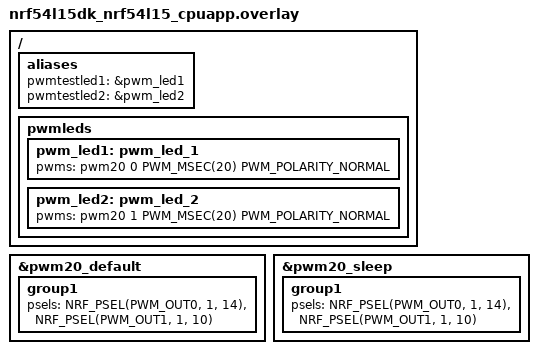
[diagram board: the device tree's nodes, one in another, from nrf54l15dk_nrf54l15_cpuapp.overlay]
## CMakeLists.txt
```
cmake_minimum_required(VERSION 3.20.0)
find_package(Zephyr REQUIRED HINTS $ENV{ZEPHYR_BASE})

project(pwm_test)

target_sources(app PRIVATE src/main.c)
```

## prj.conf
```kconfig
# Logging
CONFIG_LOG=y

# STEP 1.1 - Enable PWM
CONFIG_PWM=y
CONFIG_PWM_LOG_LEVEL_DBG=y

# STEP 1.2 - Enable LED and LED PWM
CONFIG_LED=y
CONFIG_LED_PWM=y
```

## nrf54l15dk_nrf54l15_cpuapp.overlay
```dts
// To get started, press Ctrl+Space to bring up the completion menu and view the available nodes.

// You can also use the buttons in the sidebar to perform actions on nodes.
// Actions currently available include:

// * Enabling / disabling the node
// * Adding the bus to a bus
// * Removing the node
// * Connecting ADC channels

// For more help, browse the DeviceTree documentation at https: //docs.zephyrproject.org/latest/guides/dts/index.html
// You can also visit the nRF DeviceTree extension documentation at https: //docs.nordicsemi.com/bundle/nrf-connect-vscode/page/guides/ncs_configure_app.html#devicetree-support-in-the-extension

/{
    aliases {
        pwmtestled1 = &pwm_led1;
        pwmtestled2 = &pwm_led2;
  
    };
    pwmleds {
		/*
		 * PWM signal can be exposed on GPIO pin only within same domain.
		 * There is only one domain which contains both PWM and GPIO:
		 * PWM20/21/22 and GPIO Port P1.
		 * Only LEDs connected to P1 can work with PWM, for example LED1.
		 */
		pwm_led1: pwm_led_1 {
			pwms = <&pwm20 0 PWM_MSEC(20) PWM_POLARITY_NORMAL>;
		};
        pwm_led2: pwm_led_2 {
			pwms = <&pwm20 1 PWM_MSEC(20) PWM_POLARITY_NORMAL>;
		};
	};

};
&pwm20_default {
	group1 {
		psels = <NRF_PSEL(PWM_OUT0, 1, 14)>,
				<NRF_PSEL(PWM_OUT1, 1, 10)>;
	};
};
&pwm20_sleep {
	group1 {
		psels = <NRF_PSEL(PWM_OUT0, 1, 14)>,
				<NRF_PSEL(PWM_OUT1, 1, 10)>;
	};
};
```

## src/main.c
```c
#include <sys/_intsup.h>
#include <zephyr/kernel.h>
#include <zephyr/device.h>
#include <zephyr/devicetree.h>
#include <zephyr/drivers/pwm.h>
#include <zephyr/logging/log.h>

LOG_MODULE_REGISTER(main, LOG_LEVEL_DBG);

#define PWM_PERIOD_NS   100000
#define PWM_PULSE_WIDTH 15000
// clang-format off
#define PWM_LED0        DT_ALIAS(pwmtestled1)
#define PWM_LED1        DT_ALIAS(pwmtestled2)
// #define PWM_LED0        DT_ALIAS(pwm_led0)
// this alias is defined in the devicetree as "pwm-led0", but here you should use "pwm_led0"
// clang-format on

static const struct pwm_dt_spec pwm_led0 = PWM_DT_SPEC_GET(PWM_LED0);
static const struct pwm_dt_spec pwm_led1 = PWM_DT_SPEC_GET(PWM_LED1);

int main(void) {
    int err;
    if (!pwm_is_ready_dt(&pwm_led0)) {
        LOG_ERR("Error: PWM device %s is not ready", pwm_led0.dev->name);
        return 0;
    }
    if (!pwm_is_ready_dt(&pwm_led1)) {
        LOG_ERR("Error: PWM device %s is not ready", pwm_led0.dev->name);
        return 0;
    }
    err = pwm_set_dt(&pwm_led0, PWM_PERIOD_NS, PWM_PULSE_WIDTH);
    if (err) {
        LOG_ERR("Error in pwm_set_dt(), err: %d", err);
        return 0;
    }
    err = pwm_set_dt(&pwm_led1, PWM_PERIOD_NS, PWM_PULSE_WIDTH);
    if (err) {
        LOG_ERR("Error in pwm_set_dt(), err: %d", err);
        return 0;
    }

    return 0;
}
```
